# SEC_MMR0_DBG_CTRL register map
Vendor: Texas Instruments
Peripheral module from a debugger description file (folder J7_AHP).
Registers are 32-bit, read-write, reset 0xAA00 unless marked. A register's access mark holds for its fields unless they carry their own. Offsets are as the file gives them; lines under a group give offsets from that group; [hi:lo] are bit positions; {n}, {i} and the like mark numbered series; 'fields as' and 'values as' point back to an identical list; <NAME> marks a mode.

## SEC_MMR0_DBG_CTRL
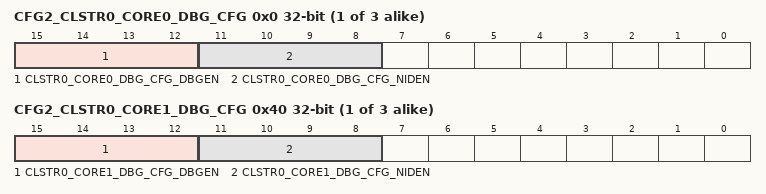
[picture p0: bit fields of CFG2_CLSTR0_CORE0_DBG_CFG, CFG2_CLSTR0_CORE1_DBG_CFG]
{0x0+0x1000*i} CFG2_CLSTR{i}_CORE0_DBG_CFG (i=0..2)
  [15:12] CLSTR{i}_CORE0_DBG_CFG_DBGEN — Core0 Invasive debug enable. This is a fault tolerant bitfield that must be set 4'hA to enable 4'b1010 - Enabled others - Disabled
  [11:8] CLSTR{i}_CORE0_DBG_CFG_NIDEN — Core0 Non-invasive debug enable. This is a fault tolerant bitfield that must be set 4'hA to enable 4'b1010 - Enabled others - Disabled
{0x40+0x1000*i} CFG2_CLSTR{i}_CORE1_DBG_CFG (i=0..2)
  [15:12] CLSTR{i}_CORE1_DBG_CFG_DBGEN — Core1 Invasive debug enable. This is a fault tolerant bitfield that must be set 4'hA to enable 4'b1010 - Enabled others - Disabled
  [11:8] CLSTR{i}_CORE1_DBG_CFG_NIDEN — Core1 Non-invasive debug enable. This is a fault tolerant bitfield that must be set 4'hA to enable 4'b1010 - Enabled others - Disabled
